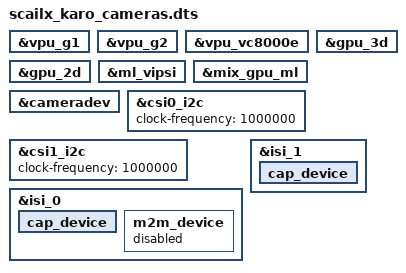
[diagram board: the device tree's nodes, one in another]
// SPDX-License-Identifier: (GPL-2.0 OR MIT)
/*
 * Copyright (C) 2023 VideologyInc
 *
 */

/dts-v1/;

#include "scailx_karo.dts"


&vpu_g1 {
	status = "okay";
};

&vpu_g2 {
	status = "okay";
};

&vpu_vc8000e {
	status = "okay";
};

// &vpu_v4l2 {
// 	status = "okay";
// };

&gpu_3d {
	status = "okay";
};

&gpu_2d {
	status = "okay";
};

&ml_vipsi {
	status = "okay";
};

&mix_gpu_ml {
	status = "okay";
};

&cameradev {
	status = "okay";
};

&csi0_i2c {
	clock-frequency = <1000000>;
};

&csi1_i2c {
	clock-frequency = <1000000>;
};

&isi_0 {
	status = "okay";

	cap_device {
		status = "okay";
	};

	m2m_device {
		status = "disabled";
	};
};

&isi_1 {
	status = "okay";

	cap_device {
		status = "okay";
	};
};

